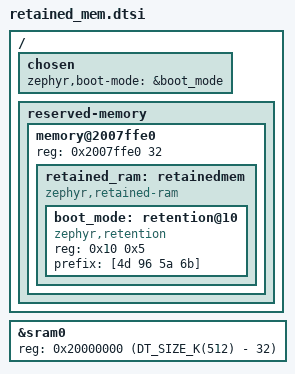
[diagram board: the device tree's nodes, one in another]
/*
 * Copyright (c) Arduino s.r.l. and/or its affiliated companies
 *
 * SPDX-License-Identifier: Apache-2.0
 */

/*
 * Warm-reset retained RAM shared by MCUboot and the loader/sketch:
 *   0x00  double-tap cookie (zephyr board double-tap.c)
 *   0x10  boot mode (1200-bps touch, double tap -> MCUboot USB DFU)
 */
&sram0 {
	reg = <0x20000000 (DT_SIZE_K(512) - 32)>;
};

/ {
	chosen {
		zephyr,boot-mode = &boot_mode;
	};

	reserved-memory {
		#address-cells = <1>;
		#size-cells = <1>;
		ranges;

		memory@2007ffe0 {
			reg = <0x2007ffe0 32>;

			retained_ram: retainedmem {
				compatible = "zephyr,retained-ram";
				status = "okay";
				#address-cells = <1>;
				#size-cells = <1>;

				boot_mode: retention@10 {
					compatible = "zephyr,retention";
					status = "okay";
					reg = <0x10 0x5>;
					prefix = [4d 96 5a 6b];
				};
			};
		};
	};
};
